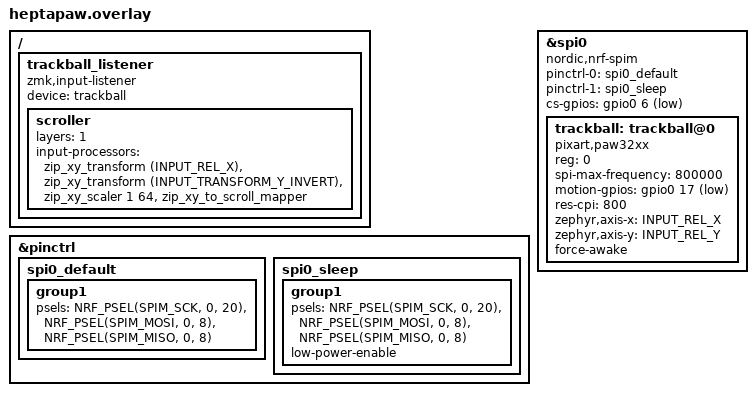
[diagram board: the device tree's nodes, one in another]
/*
 * Copyright (c) 2020 Pete Johanson
 *
 * SPDX-License-Identifier: MIT
 */

#include "heptapaw.dtsi"
#include <input/processors.dtsi>
#include <dt-bindings/zmk/input_transform.h>
#include <zephyr/dt-bindings/input/input-event-codes.h>

&pinctrl {
    spi0_default: spi0_default {
        group1 {
            psels = <NRF_PSEL(SPIM_SCK, 0, 20)>,
                    <NRF_PSEL(SPIM_MOSI, 0, 8)>,
                    <NRF_PSEL(SPIM_MISO, 0, 8)>;
        };
    };

    spi0_sleep: spi0_sleep {
        group1 {
            psels = <NRF_PSEL(SPIM_SCK, 0, 20)>,
                    <NRF_PSEL(SPIM_MOSI, 0, 8)>,
                    <NRF_PSEL(SPIM_MISO, 0, 8)>;
            low-power-enable;
        };
    };
};

&spi0 {
    status = "okay";
    compatible = "nordic,nrf-spim";
    pinctrl-0 = <&spi0_default>;
    pinctrl-1 = <&spi0_sleep>;
    pinctrl-names = "default", "sleep";
    cs-gpios = <&gpio0 6 GPIO_ACTIVE_LOW>;

    trackball: trackball@0 {
        status = "okay";
        compatible = "pixart,paw32xx";
        reg = <0>;
        spi-max-frequency = <800000>;
        motion-gpios = <&gpio0 17 (GPIO_ACTIVE_LOW | GPIO_PULL_UP)>;
        res-cpi = <800>;
        zephyr,axis-x = <INPUT_REL_X>;
        zephyr,axis-y = <INPUT_REL_Y>;
        force-awake;
    };
};

/ {
  trackball_listener {
    compatible = "zmk,input-listener";
    device = <&trackball>;
    scroller {
            layers = <1>;
            //process-next;
            input-processors = 
            <&zip_xy_transform (INPUT_REL_X)>,
            <&zip_xy_transform (INPUT_TRANSFORM_Y_INVERT)>,
            <&zip_xy_scaler 1 64>,<&zip_xy_to_scroll_mapper>;
        };
    };
};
